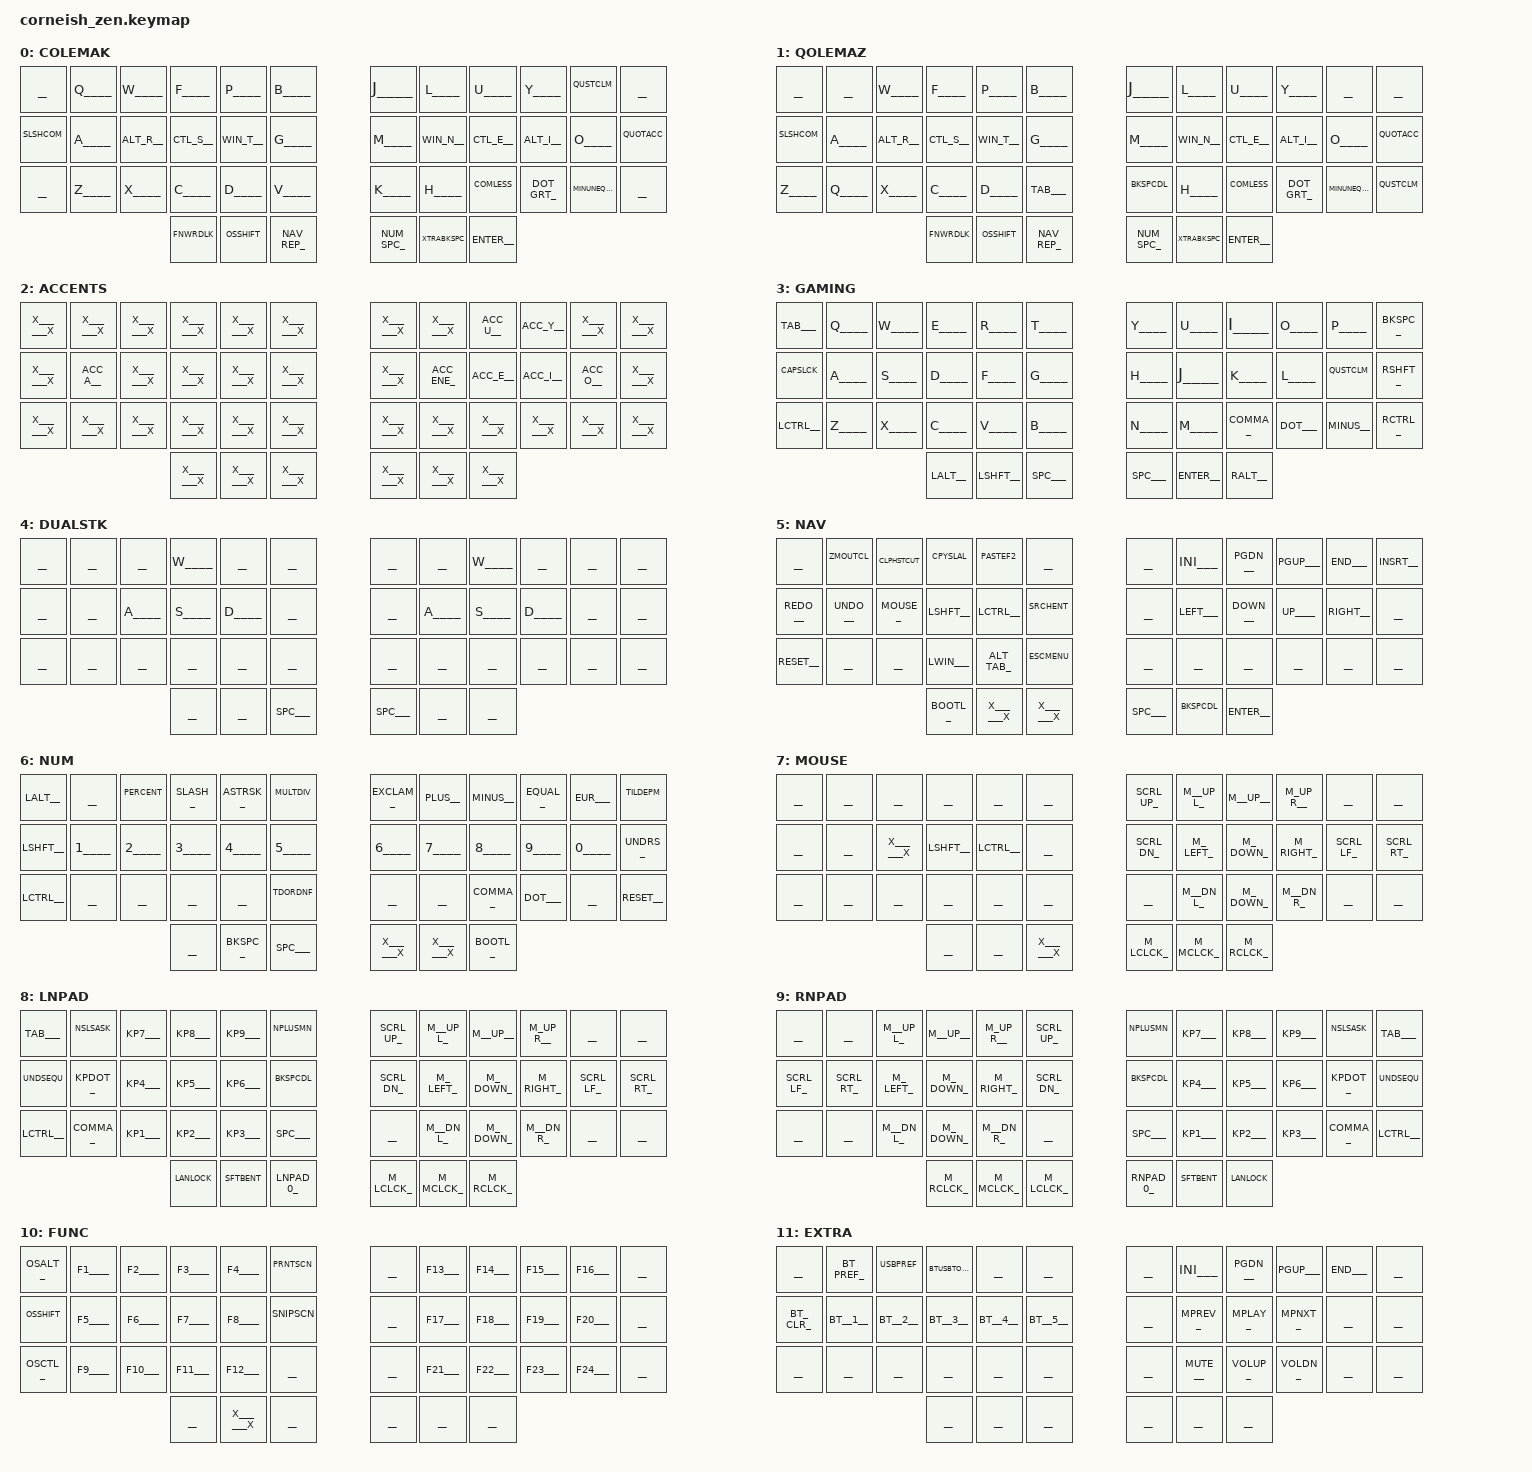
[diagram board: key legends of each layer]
/*
*
* Copyright (c) 2021 Darryl deHaan
* SPDX-License-Identifier: MIT
*
*/

#include <behaviors.dtsi>
#include <dt-bindings/zmk/keys.h>
#include <dt-bindings/zmk/bt.h>
#include <dt-bindings/zmk/outputs.h>

#define TEST 0
#define COLEMAK 1
#define QOLEMAZ 2
#define ACCENTS 3
#define GAMING  4
#define DUALSTK 5
#define NAV 6
#define NUM 7
#define MOUSE 8
#define LNPAD 9
#define RNPAD 10
#define FUNC 11
#define EXTRA 12


#define TEST44s


#include "keycodes.h"
#include <dt-bindings/zmk/mouse.h>

/ {
  chosen {
    zmk,matrix_transform = &default_transform;
    //zmk,matrix_transform = &five_column_transform;
  };
};

&sk {
      release-after-ms = <1500>;
      quick-release;
};  
&mmv {    time-to-max-speed-ms = <1000>;};

/ {

        combos {
              #include "combos.dtsi"
        };
        macros {
              #include "macros.dtsi"
        };
        behaviors {

              #include "behaviors.dtsi"
        };

     
        keymap {
                compatible = "zmk,keymap";




//  Base Layer: TEST
//  ╔═════════╤═════════╤═════════╤═════════╤═════════╤═════════╗                       ╔═════════╤═════════╤═════════╤═════════╤═════════╤═════════╗
//  ║    B    │    Q    │    W    │    F    │    P    │    B    ║                       ║    J    │    L    │    U    │    Y    │    B    │    J    ║
//  ║         │         │         │         │         │         ║                       ║         │         │         │         │         │         ║
//  ╟─────────┼─────────┼─────────┼─────────┼─────────┼─────────╢                       ╟─────────┼─────────┼─────────┼─────────┼─────────┼─────────╢
//  ║    M    │    A    │    R    │    S    │    T    │    G    ║                       ║    M    │    N    │    E    │    I    │    O    │    S    ║
//  ║         │         │         │         │         │         ║                       ║         │         │         │         │         │         ║
//  ╟─────────┼─────────┼─────────┼─────────┼─────────┼─────────║                       ║─────────┼─────────┼─────────┼─────────┼─────────┼─────────╢
//  ║    D    │    Z    │    X    │    C    │    D    │    V    ║                       ║    K    │    H    │    K    │    S    │    J    │   U     ║
//  ║         │         │         │         │         │         ║                       ║         │         │         │         │         │         ║
//  ╚═════════╧═════════╧═════════╧═════════╬─────────┼─────────╬═════════╗   ╔═════════╬─────────┼─────────╬═════════╧═════════╧═════════╧═════════╝
//                                          ║    F    │    P    │    B    ║   ║    J    │    L    │    U    ║
//                                          ║         │         │         ║   ║         │         │         ║
//                                          ╚═════════╧═════════╧═════════╝   ╚═════════╧═════════╧═════════╝
                default_layer { label = "TEST"; bindings = <
     ____B____ ____Q____ ____W____ ____F____ ____P____ ____B____                         ____J____ ____L____ ____U____ ____Y____ ____B____ ____J____
     ____M____ ____A____ ____R____ ____S____ ____T____ ____G____                         ____M____ ____N____ ____E____ ____I____ ____O____ ____S____
     ____D____ ____Z____ ____X____ ____C____ ____D____ ____V____                         ____K____ ____H____ ____K____ ____S____ ____J____ ____U____
                                             ____F____ ____P____ ____B____     ____J____ ____L____ ____U____
                        >;};


//  Base Layer: COLEMAK
//  ╔═════════╤═════════╤═════════╤═════════╤═════════╤═════════╗                       ╔═════════╤═════════╤═════════╤═════════╤═════════╤═════════╗
//  ║         │    Q    │    W    │    F    │    P    │    B    ║                       ║    J    │    L    │    U    │    Y    │   ¡ !   │         ║
//  ║         │         │         │         │         │         ║                       ║         │         │         │         │   ¿ ?   │         ║
//  ╟─────────┼─────────┼─────────┼─────────┼─────────┼─────────╢                       ╟─────────┼─────────┼─────────┼─────────┼─────────┼─────────╢
//  ║  */ /*  │    A    │   ALT   │   CTRL  │   WIN   │    G    ║                       ║    M    │   WIN   │   CTRL  │   ALT   │    O    │   ^ `   ║
//  ║   / \   │         │    R    │    S    │    T    │         ║                       ║         │    N    │    E    │    I    │         │   " '   ║
//  ╟─────────┼─────────┼─────────┼─────────┼─────────┼─────────║                       ║─────────┼─────────┼─────────┼─────────┼─────────┼─────────╢
//  ║         │    Z    │    X    │    C    │    D    │    V    ║                       ║    K    │    H    │   , ;   │   . :   │  → =    │         ║
//  ║         │         │         │         │         │         ║                       ║         │         │         │         │  - _    │         ║
//  ╚═════════╧═════════╧═════════╧═════════╬─────────┼─────────╬═════════╗   ╔═════════╬─────────┼─────────╬═════════╧═════════╧═════════╧═════════╝
//                                          ║ CAPSLCK │  CAPS   │   NAV   ║   ║   NUM   │  EXTRA  │  ENTER  ║
//                                          ║FNC CPWRD│  SHIFT  │   REP   ║   ║   SPC   │  BKSPC  │         ║
//                                          ╚═════════╧═════════╧═════════╝   ╚═════════╧═════════╧═════════╝
                default_layer { label = "COLEMAK"; bindings = <
     _________ ____Q____ ____W____ ____F____ ____P____ ____B____                         ____J____ ____L____ ____U____ ____Y____ _QUSTCLM_ _________
     _SLSHCOM_ ____A____ __ALT_R__ __CTL_S__ __WIN_T__ ____G____                         ____M____ __WIN_N__ __CTL_E__ __ALT_I__ ____O____ _QUOTACC_
     _________ ____Z____ ____X____ ____C____ ____D____ ____V____                         ____K____ ____H____ _COMLESS_ _DOT_GRT_ MINUNEQAR _________
                                             _FNWRDLK_ _OSSHIFT_ _NAV_REP_     _NUM_SPC_ XTRABKSPC __ENTER__
                        >;};

//  Base Layer: QOLEMAZ
//  ╔═════════╤═════════╤═════════╤═════════╤═════════╤═════════╗                       ╔═════════╤═════════╤═════════╤═════════╤═════════╤═════════╗
//  ║         │         │    W    │    F    │    P    │    B    ║                       ║    J    │    L    │    U    │    Y    │         │         ║
//  ║         │         │         │         │         │         ║                       ║         │         │         │         │         │         ║
//  ╟─────────┼─────────┼─────────┼─────────┼─────────┼─────────╢                       ╟─────────┼─────────┼─────────┼─────────┼─────────┼─────────╢
//  ║  */ /*  │    A    │   ALT   │   CTRL  │   WIN   │    G    ║                       ║    M    │   WIN   │   CTRL  │   ALT   │    O    │   ^ `   ║
//  ║   / \   │         │    R    │    S    │    T    │         ║                       ║         │    N    │    E    │    I    │         │   " '   ║
//  ╟─────────┼─────────┼─────────┼─────────┼─────────┼─────────║                       ║─────────┼─────────┼─────────┼─────────┼─────────┼─────────╢
//  ║    Z    │    Q    │    X    │    C    │    D    │   TAB   ║                       ║   DEL   │    H    │   , ;   │   . :   │  → =    │   ¡ !   ║
//  ║         │         │         │         │         │         ║                       ║ BACKSPC │         │         │         │  - _    │   ¿ ?   ║
//  ╚═════════╧═════════╧═════════╧═════════╬─────────┼─────────╬═════════╗   ╔═════════╬─────────┼─────────╬═════════╧═════════╧═════════╧═════════╝
//                                          ║ CAPSLCK │  CAPS   │   NAV   ║   ║   NUM   │  EXTRA  │  ENTER  ║
//                                          ║FNC CPWRD│  SHIFT  │   REP   ║   ║   SPC   │  BKSPC  │         ║
//                                          ╚═════════╧═════════╧═════════╝   ╚═════════╧═════════╧═════════╝
                qolemaz_layer { label = "QOLEMAZ"; bindings = <
     _________ _________ ____W____ ____F____ ____P____ ____B____                         ____J____ ____L____ ____U____ ____Y____ _________ _________
     _SLSHCOM_ ____A____ __ALT_R__ __CTL_S__ __WIN_T__ ____G____                         ____M____ __WIN_N__ __CTL_E__ __ALT_I__ ____O____ _QUOTACC_
     ____Z____ ____Q____ ____X____ ____C____ ____D____ ___TAB___                         _BKSPCDL_ ____H____ _COMLESS_ _DOT_GRT_ MINUNEQAR _QUSTCLM_
                                             _FNWRDLK_ _OSSHIFT_ _NAV_REP_     _NUM_SPC_ XTRABKSPC __ENTER__
                        >;};
             


//  Base Layer: ACCENTS
//  ╔═════════╤═════════╤═════════╤═════════╤═════════╤═════════╗                       ╔═════════╤═════════╤═════════╤═════════╤═════════╤═════════╗
//  ║         │         │         │         │         │         ║                       ║         │         │    Ú    │    Ü    │         │         ║
//  ║         │         │         │         │         │         ║                       ║         │         │    U    │    Y    │         │         ║
//  ╟─────────┼─────────┼─────────┼─────────┼─────────┼─────────╢                       ╟─────────┼─────────┼─────────┼─────────┼─────────┼─────────╢
//  ║         │    Á    │         │         │         │         ║                       ║         │    Ñ    │    É    │    Í    │    Ó    │         ║
//  ║         │    A    │         │         │         │         ║                       ║         │    N    │    E    │    I    │    O    │         ║
//  ╟─────────┼─────────┼─────────┼─────────┼─────────┼─────────║                       ║─────────┼─────────┼─────────┼─────────┼─────────┼─────────╢
//  ║         │         │         │         │         │         ║                       ║         │         │         │         │         │         ║
//  ║         │         │         │         │         │         ║                       ║         │         │         │         │         │         ║
//  ╚═════════╧═════════╧═════════╧═════════╬─────────┼─────────╬═════════╗   ╔═════════╬─────────┼─────────╬═════════╧═════════╧═════════╧═════════╝
//                                          ║         │         │         ║   ║         │         │         ║
//                                          ║         │         │         ║   ║         │         │         ║
//                                          ╚═════════╧═════════╧═════════╝   ╚═════════╧═════════╧═════════╝
                letter_accents_layer { label = "ACCENTS"; bindings = <
     X_______X X_______X X_______X X_______X X_______X X_______X                         X_______X X_______X __ACC_U__ __ACC_Y__ X_______X X_______X
     X_______X __ACC_A__ X_______X X_______X X_______X X_______X                         X_______X _ACC_ENE_ __ACC_E__ __ACC_I__ __ACC_O__ X_______X
     X_______X X_______X X_______X X_______X X_______X X_______X                         X_______X X_______X X_______X X_______X X_______X X_______X
                                             X_______X X_______X X_______X     X_______X X_______X X_______X
                        >;};

//  Base Layer: GAMING
//  ╔═════════╤═════════╤═════════╤═════════╤═════════╤═════════╗                       ╔═════════╤═════════╤═════════╤═════════╤═════════╤═════════╗
//  ║  TAB    │    Q    │    W    │    E    │    R    │    T    ║                       ║    Y    │    U    │    I    │    O    │    P    │ BCKSPC  ║
//  ║         │         │         │         │         │         ║                       ║         │         │         │         │         │         ║
//  ╟─────────┼─────────┼─────────┼─────────┼─────────┼─────────╢                       ╟─────────┼─────────┼─────────┼─────────┼─────────┼─────────╢
//  ║ CAPSLCK │    A    │    S    │    D    │    F    │    G    ║                       ║    H    │    J    │    K    │    L    │   ! ¡   │  RSHFT  ║
//  ║         │         │         │         │         │         ║                       ║         │         │         │         │   ? ¿   │         ║
//  ╟─────────┼─────────┼─────────┼─────────┼─────────┼─────────║                       ║─────────┼─────────┼─────────┼─────────┼─────────┼─────────╢
//  ║  LCTRL  │    Z    │    X    │    C    │    V    │    B    ║                       ║    N    │    M    │   , ;   │   . :   │  - _    │  RCTRL  ║
//  ║         │         │         │         │         │         ║                       ║         │         │         │         │         │         ║
//  ╚═════════╧═════════╧═════════╧═════════╬─────────┼─────────╬═════════╗   ╔═════════╬─────────┼─────────╬═════════╧═════════╧═════════╧═════════╝
//                                          ║  LALT   │  SHIFT  │   SPC   ║   ║   SPC   │  ENTER  │  RALT   ║
//                                          ║         │         │         ║   ║         │         │         ║
//                                          ╚═════════╧═════════╧═════════╝   ╚═════════╧═════════╧═════════╝
                gaming_layer { label = "GAMING"; bindings = <
     ___TAB___ ____Q____ ____W____ ____E____ ____R____ ____T____                         ____Y____ ____U____ ____I____ ____O____ ____P____ __BKSPC__
     _CAPSLCK_ ____A____ ____S____ ____D____ ____F____ ____G____                         ____H____ ____J____ ____K____ ____L____ _QUSTCLM_ __RSHFT__
     __LCTRL__ ____Z____ ____X____ ____C____ ____V____ ____B____                         ____N____ ____M____ __COMMA__ ___DOT___ __MINUS__ __RCTRL__
                                             ___LALT__ __LSHFT__ ___SPC___     ___SPC___ __ENTER__ ___RALT__
                        >;};


//  Base Layer: DUALSTK
//  ╔═════════╤═════════╤═════════╤═════════╤═════════╤═════════╗                       ╔═════════╤═════════╤═════════╤═════════╤═════════╤═════════╗
//  ║         │         │         │    W    │         │         ║                       ║         │         │    W    │         │         │         ║
//  ║         │         │         │         │         │         ║                       ║         │         │         │         │         │         ║
//  ╟─────────┼─────────┼─────────┼─────────┼─────────┼─────────╢                       ╟─────────┼─────────┼─────────┼─────────┼─────────┼─────────╢
//  ║         │         │    A    │    S    │    D    │         ║                       ║         │    A    │    S    │    D    │         │         ║
//  ║         │         │         │         │         │         ║                       ║         │         │         │         │         │         ║
//  ╟─────────┼─────────┼─────────┼─────────┼─────────┼─────────║                       ║─────────┼─────────┼─────────┼─────────┼─────────┼─────────╢
//  ║         │         │         │         │         │         ║                       ║         │         │         │         │         │         ║
//  ║         │         │         │         │         │         ║                       ║         │         │         │         │         │         ║
//  ╚═════════╧═════════╧═════════╧═════════╬─────────┼─────────╬═════════╗   ╔═════════╬─────────┼─────────╬═════════╧═════════╧═════════╧═════════╝
//                                          ║         │         │   SPC   ║   ║   SPC   │         │         ║
//                                          ║         │         │         ║   ║         │         │         ║
//                                          ╚═════════╧═════════╧═════════╝   ╚═════════╧═════════╧═════════╝
                dual_stick_layer { label = "DUALSTK"; bindings = <
     _________ _________ _________ ____W____ _________ _________                         _________ _________ ____W____ _________ _________ _________
     _________ _________ ____A____ ____S____ ____D____ _________                         _________ ____A____ ____S____ ____D____ _________ _________
     _________ _________ _________ _________ _________ _________                         _________ _________ _________ _________ _________ _________
                                             _________ _________ ___SPC___     ___SPC___ _________ _________
                        >;};



//  Base Layer: NAV
//  ╔═════════╤═════════╤═════════╤═════════╤═════════╤═════════╗                       ╔═════════╤═════════╤═════════╤═════════╤═════════╤═════════╗
//  ║         │ZOOM  CLS│CLIP HIST│SELECTALL│   F2    │         ║                       ║         │   INI   │  PREPAG │  AVPAG  │   END   │  INSERT ║
//  ║         │ZOOM +/- │   CUT   │  COPY   │  PASTE  │         ║                       ║         │         │         │         │         │         ║
//  ╟─────────┼─────────┼─────────┼─────────┼─────────┼─────────╢                       ╟─────────┼─────────┼─────────┼─────────┼─────────┼─────────╢
//  ║  REDO   │  UNDO   │  MOUSE  │  SHIFT  │  CTRL   │ SEARCH  ║                       ║         │  LEFT   │  DOWN   │   UP    │  RIGHT  │         ║
//  ║         │         │         │         │         │  ENTER  ║                       ║         │         │         │         │         │         ║
//  ╟─────────┼─────────┼─────────┼─────────┼─────────┼─────────║                       ║─────────┼─────────┼─────────┼─────────┼─────────┼─────────╢
//  ║  RESET  │         │         │  LWIN   │ ALT+TAB │   MENU  ║                       ║         │         │         │         │         │         ║
//  ║  SOFT   │         │         │         │         │   ESC   ║                       ║         │         │         │         │         │         ║
//  ╚═════════╧═════════╧═════════╧═════════╬─────────┼─────────╬═════════╗   ╔═════════╬─────────┼─────────╬═════════╧═════════╧═════════╧═════════╝
//                                          ║  RESET  │         │XXXXXXXXX║   ║   SPC   │   DEL   │  ENTER  ║
//                                          ║  BOOTL  │         │XXXXXXXXX║   ║         │  BKSPC  │         ║
//                                          ╚═════════╧═════════╧═════════╝   ╚═════════╧═════════╧═════════╝
                navigation_layer { label = "NAV"; bindings = <
     _________ _ZMOUTCL_ CLPHSTCUT _CPYSLAL_ _PASTEF2_ _________                         _________ ___INI___ __PGDN___ __PGUP___ ___END___ __INSRT__
     __REDO___ __UNDO___ __MOUSE__ __LSHFT__ __LCTRL__ _SRCHENT_                         _________ __LEFT___ __DOWN___ ___UP____ __RIGHT__ _________
     __RESET__ _________ _________ __LWIN___ _ALT_TAB_ _ESCMENU_                         _________ _________ _________ _________ _________ _________
                                             __BOOTL__ X_______X X_______X     ___SPC___ _BKSPCDL_ __ENTER__
                        >;};



//  Base Layer: NUM
//  ╔═════════╤═════════╤═════════╤═════════╤═════════╤═════════╗                       ╔═════════╤═════════╤═════════╤═════════╤═════════╤═════════╗
//  ║   ALT   │         │    %    │    /    │    *    │    ÷    ║                       ║    !    │    +    │    -    │    =    │    €    │    ±    ║
//  ║         │         │         │         │         │    ×    ║                       ║         │         │         │         │         │    ~    ║
//  ╟─────────┼─────────┼─────────┼─────────┼─────────┼─────────╢                       ╟─────────┼─────────┼─────────┼─────────┼─────────┼─────────╢
//  ║  SHIFT  │    1    │    2    │    3    │    4    │    5    ║                       ║    6    │    7    │    8    │    9    │    0    │    _    ║
//  ║         │         │         │         │         │         ║                       ║         │         │         │         │         │         ║
//  ╟─────────┼─────────┼─────────┼─────────┼─────────┼─────────║                       ║─────────┼─────────┼─────────┼─────────┼─────────┼─────────╢
//  ║  LCTRL  │         │         │         │         │  ¼ ½ ∞  ║                       ║         │         │    ,    │    .    │         │  RESET  ║
//  ║         │         │         │         │         │  ³ ² º  ║                       ║         │         │         │         │         │  SOFT   ║
//  ╚═════════╧═════════╧═════════╧═════════╬─────────┼─────────╬═════════╗   ╔═════════╬─────────┼─────────╬═════════╧═════════╧═════════╧═════════╝
//                                          ║         │ BCKSPC  │   SPC   ║   ║XXXXXXXXX│         │  RESET  ║
//                                          ║         │         │         ║   ║XXXXXXXXX│         │  BOOTL  ║
//                                          ╚═════════╧═════════╧═════════╝   ╚═════════╧═════════╧═════════╝
//  
                num_layer { label = "NUM"; bindings = <
     ___LALT__ _________ _PERCENT_ __SLASH__ _ASTRSK__ _MULTDIV_                         _EXCLAM__ ___PLUS__ __MINUS__ __EQUAL__ ___EUR___ _TILDEPM_
     __LSHFT__ ____1____ ____2____ ____3____ ____4____ ____5____                         ____6____ ____7____ ____8____ ____9____ ____0____ __UNDRS__
     __LCTRL__ _________ _________ _________ _________ _TDORDNF_                         _________ _________ __COMMA__ ___DOT___ _________ __RESET__
                                             _________ __BKSPC__ ___SPC___     X_______X X_______X __BOOTL__
                        >;};


//  Base Layer: MOUSE
//  ╔═════════╤═════════╤═════════╤═════════╤═════════╤═════════╗                       ╔═════════╤═════════╤═════════╤═════════╤═════════╤═════════╗
//  ║         │         │         │         │         │         ║                       ║ SCROLL  │   U-L   │    U    │   U-R   │         │         ║
//  ║         │         │         │         │         │         ║                       ║   UP    │         │         │         │         │         ║
//  ╟─────────┼─────────┼─────────┼─────────┼─────────┼─────────╢                       ╟─────────┼─────────┼─────────┼─────────┼─────────┼─────────╢
//  ║         │         │XXXXXXXXX│  SHIFT  │  CTRL   │         ║                       ║ SCROLL  │    L    │    D    │    R    │ SCROLL  │ SCROLL  ║
//  ║         │         │XXXXXXXXX│         │         │         ║                       ║   DN    │         │         │         │  LEFT   │  RIGHT  ║
//  ╟─────────┼─────────┼─────────┼─────────┼─────────┼─────────║                       ║─────────┼─────────┼─────────┼─────────┼─────────┼─────────╢
//  ║         │         │         │         │         │         ║                       ║         │   D-L   │    D    │   D-R   │         │         ║
//  ║         │         │         │         │         │         ║                       ║         │         │         │         │         │         ║
//  ╚═════════╧═════════╧═════════╧═════════╬─────────┼─────────╬═════════╗   ╔═════════╬─────────┼─────────╬═════════╧═════════╧═════════╧═════════╝
//                                          ║         │         │XXXXXXXXX║   ║  LEFT   │   MID   │  RIGHT  ║
//                                          ║         │         │XXXXXXXXX║   ║  CLICK  │  CLICK  │  CLICK  ║
//                                          ╚═════════╧═════════╧═════════╝   ╚═════════╧═════════╧═════════╝
//  
                mouse_layer { label = "MOUSE"; bindings = <
     _________ _________ _________ _________ _________ _________                         _SCRL_UP_ _M__UP_L_ __M__UP__ _M_UP_R__ _________ _________
     _________ _________ X_______X __LSHFT__ __LCTRL__ _________                         _SCRL_DN_ _M__LEFT_ _M__DOWN_ _M_RIGHT_ _SCRL_LF_ _SCRL_RT_
     _________ _________ _________ _________ _________ _________                         _________ _M__DN_L_ _M__DOWN_ _M__DN_R_ _________ _________
                                             _________ _________ X_______X     _M_LCLCK_ _M_MCLCK_ _M_RCLCK_
                        >;};




//  Base Layer: LNPAD
//  ╔═════════╤═════════╤═════════╤═════════╤═════════╤═════════╗                       ╔═════════╤═════════╤═════════╤═════════╤═════════╤═════════╗
//  ║   TAB   │    *    │    7    │    8    │    9    │    -    ║                       ║ SCROLL  │   U-L   │    U    │   U-R   │         │         ║
//  ║         │    /    │         │         │         │    +    ║                       ║   UP    │         │         │         │         │         ║
//  ╟─────────┼─────────┼─────────┼─────────┼─────────┼─────────╢                       ╟─────────┼─────────┼─────────┼─────────┼─────────┼─────────╢
//  ║  EQUAL  │    .    │    4    │    5    │    6    │ DELETE  ║                       ║ SCROLL  │    L    │    D    │    R    │ SCROLL  │ SCROLL  ║
//  ║ UNDERSC │         │         │         │         │ BCKSPC  ║                       ║   DN    │         │         │         │  LEFT   │  RIGHT  ║
//  ╟─────────┼─────────┼─────────┼─────────┼─────────┼─────────║                       ║─────────┼─────────┼─────────┼─────────┼─────────┼─────────╢
//  ║  LCTRL  │    ,    │    1    │    2    │    3    │   SPC   ║                       ║         │   D-L   │    D    │   D-R   │         │         ║
//  ║         │         │         │         │         │         ║                       ║         │         │         │         │         │         ║
//  ╚═════════╧═════════╧═════════╧═════════╬─────────┼─────────╬═════════╗   ╔═════════╬─────────┼─────────╬═════════╧═════════╧═════════╧═════════╝
//                                          ║  LALT   │ LSHIFT  │XXXXXXXXX║   ║  LEFT   │   MID   │  RIGHT  ║
//                                          ║  NLOCK  │  ENTER  │XXXXXXXXX║   ║  CLICK  │  CLICK  │  CLICK  ║
//                                          ╚═════════╧═════════╧═════════╝   ╚═════════╧═════════╧═════════╝
//  
                left_numpad_layer { label = "LNPAD"; bindings = <
     ___TAB___ _NSLSASK_ ___KP7___ ___KP8___ ___KP9___ _NPLUSMN_                         _SCRL_UP_ _M__UP_L_ __M__UP__ _M_UP_R__ _________ _________
     _UNDSEQU_ __KPDOT__ ___KP4___ ___KP5___ ___KP6___ _BKSPCDL_                         _SCRL_DN_ _M__LEFT_ _M__DOWN_ _M_RIGHT_ _SCRL_LF_ _SCRL_RT_
     __LCTRL__ __COMMA__ ___KP1___ ___KP2___ ___KP3___ ___SPC___                         _________ _M__DN_L_ _M__DOWN_ _M__DN_R_ _________ _________
                                             _LANLOCK_ _SFTBENT_ _LNPAD_0_     _M_LCLCK_ _M_MCLCK_ _M_RCLCK_
                        >;};



//  Base Layer: RNPAD
//  ╔═════════╤═════════╤═════════╤═════════╤═════════╤═════════╗                       ╔═════════╤═════════╤═════════╤═════════╤═════════╤═════════╗
//  ║         │         │   U-L   │    U    │   U-R   │ SCROLL  ║                       ║    -    │    7    │    8    │    9    │    *    │   TAB   ║
//  ║         │         │         │         │         │   UP    ║                       ║    +    │         │         │         │    /    │         ║
//  ╟─────────┼─────────┼─────────┼─────────┼─────────┼─────────╢                       ╟─────────┼─────────┼─────────┼─────────┼─────────┼─────────╢
//  ║ SCROLL  │ SCROLL  │    L    │    D    │    R    │ SCROLL  ║                       ║ DELETE  │    4    │    5    │    6    │    .    │  EQUAL  ║
//  ║         │         │         │         │         │   DN    ║                       ║ BCKSPC  │         │         │         │         │ UNDERSC ║
//  ╟─────────┼─────────┼─────────┼─────────┼─────────┼─────────║                       ║─────────┼─────────┼─────────┼─────────┼─────────┼─────────╢
//  ║         │         │   D-L   │   D-L   │   D-R   │   D-L   ║                       ║   SPC   │    1    │    2    │    3    │    ,    │  RCTRL  ║
//  ║         │         │         │         │         │         ║                       ║         │         │         │         │         │         ║
//  ╚═════════╧═════════╧═════════╧═════════╬─────────┼─────────╬═════════╗   ╔═════════╬─────────┼─────────╬═════════╧═════════╧═════════╧═════════╝
//                                          ║  RIGHT  │   MID   │  LEFT   ║   ║XXXXXXXXX│ LSHIFT  │  LALT   ║
//                                          ║  CLICK  │  CLICK  │  CLICK  ║   ║XXXXXXXXX│  ENTER  │  NLOCK  ║
//                                          ╚═════════╧═════════╧═════════╝   ╚═════════╧═════════╧═════════╝
//  
                right_numpad_layer { label = "RNPAD"; bindings = <
     _________ _________ _M__UP_L_ __M__UP__ _M_UP_R__ _SCRL_UP_                         _NPLUSMN_ ___KP7___ ___KP8___ ___KP9___ _NSLSASK_ ___TAB___
     _SCRL_LF_ _SCRL_RT_ _M__LEFT_ _M__DOWN_ _M_RIGHT_ _SCRL_DN_                         _BKSPCDL_ ___KP4___ ___KP5___ ___KP6___ __KPDOT__ _UNDSEQU_
     _________ _________ _M__DN_L_ _M__DOWN_ _M__DN_R_ _________                         ___SPC___ ___KP1___ ___KP2___ ___KP3___ __COMMA__ __LCTRL__
                                             _M_RCLCK_ _M_MCLCK_ _M_LCLCK_     _RNPAD_0_ _SFTBENT_ _LANLOCK_
                        >;};




//  Base Layer: FUNC
//  ╔═════════╤═════════╤═════════╤═════════╤═════════╤═════════╗                       ╔═════════╤═════════╤═════════╤═════════╤═════════╤═════════╗
//  ║ ONESHOT │   F1    │   F2    │   F3    │   F4    │  PRINT  ║                       ║         │   F13   │   F14   │   F15   │   F16   │         ║
//  ║   ALT   │         │         │         │         │ SCREEN  ║                       ║         │         │         │         │         │         ║
//  ╟─────────┼─────────┼─────────┼─────────┼─────────┼─────────╢                       ╟─────────┼─────────┼─────────┼─────────┼─────────┼─────────╢
//  ║ ONESHOT │   F5    │   F6    │   F7    │   F8    │  SNIP   ║                       ║         │   F17   │   F18   │   F19   │   F20   │         ║
//  ║  SHIFT  │         │         │         │         │ SCREEN  ║                       ║         │         │         │         │         │         ║
//  ╟─────────┼─────────┼─────────┼─────────┼─────────┼─────────║                       ║─────────┼─────────┼─────────┼─────────┼─────────┼─────────╢
//  ║ ONESHOT │   F9    │   F10   │   F11   │   F12   │         ║                       ║         │   F21   │   F22   │   F23   │   F24   │         ║
//  ║  CTRL   │         │         │         │         │         ║                       ║         │         │         │         │         │         ║
//  ╚═════════╧═════════╧═════════╧═════════╬─────────┼─────────╬═════════╗   ╔═════════╬─────────┼─────────╬═════════╧═════════╧═════════╧═════════╝
//                                          ║         │XXXXXXXXX│         ║   ║         │         │         ║
//                                          ║         │XXXXXXXXX│         ║   ║         │         │         ║
//                                          ╚═════════╧═════════╧═════════╝   ╚═════════╧═════════╧═════════╝
//  

                function_layer { label = "FUNC"; bindings = <
     __OSALT__ ___F1____ ___F2____ ___F3____ ___F4____ _PRNTSCN_                         _________ ___F13___ ___F14___ ___F15___ ___F16___ _________
     _OSSHIFT_ ___F5____ ___F6____ ___F7____ ___F8____ _SNIPSCN_                         _________ ___F17___ ___F18___ ___F19___ ___F20___ _________
     __OSCTL__ ___F9____ ___F10___ ___F11___ ___F12___ _________                         _________ ___F21___ ___F22___ ___F23___ ___F24___ _________
                                             _________ X_______X _________     _________ _________ _________
                        >;};


//  Base Layer: EXTRA
//  ╔═════════╤═════════╤═════════╤═════════╤═════════╤═════════╗                       ╔═════════╤═════════╤═════════╤═════════╤═════════╤═════════╗
//  ║         │   BT    │   USB   │ BT  USB │         │         ║                       ║         │   INI   │  AVPAG  │ PREPAG  │   END   │         ║
//  ║         │PREFERRED│PREFERRED│ TOGGLE  │         │         ║                       ║         │         │         │         │         │         ║
//  ╟─────────┼─────────┼─────────┼─────────┼─────────┼─────────╢                       ╟─────────┼─────────┼─────────┼─────────┼─────────┼─────────╢
//  ║   BT    │   BT    │   BT    │   BT    │   BT    │   BT    ║                       ║         │  MEDIA  │  MEDIA  │  MEDIA  │         │         ║
//  ║  CLEAR  │    1    │    2    │    3    │    4    │    5    ║                       ║         │  PREV   │  PLAY   │  NEXT   │         │         ║
//  ╟─────────┼─────────┼─────────┼─────────┼─────────┼─────────║                       ║─────────┼─────────┼─────────┼─────────┼─────────┼─────────╢
//  ║         │         │         │         │         │         ║                       ║         │   VOL   │   VOL   │   VOL   │         │         ║
//  ║         │         │         │         │         │         ║                       ║         │  MUTE   │    UP   │   DWN   │         │         ║
//  ╚═════════╧═════════╧═════════╧═════════╬─────────┼─────────╬═════════╗   ╔═════════╬─────────┼─────────╬═════════╧═════════╧═════════╧═════════╝
//                                          ║         │         │         ║   ║         │         │         ║
//                                          ║         │         │         ║   ║         │         │         ║
//                                          ╚═════════╧═════════╧═════════╝   ╚═════════╧═════════╧═════════╝
//  

                extra_layer { label = "EXTRA"; bindings = <
     _________ _BT_PREF_ _USBPREF_ BTUSBTOGG _________ _________                         _________ ___INI___ __PGDN___ __PGUP___ ___END___ _________
     _BT__CLR_ __BT__1__ __BT__2__ __BT__3__ __BT__4__ __BT__5__                         _________ __MPREV__ __MPLAY__ __MPNXT__ _________ _________
     _________ _________ _________ _________ _________ _________                         _________ __MUTE___ __VOLUP__ __VOLDN__ _________ _________
                                             _________ _________ _________     _________ _________ _________
                        >;};




//  Base Layer: BLANK
//  ╔═════════╤═════════╤═════════╤═════════╤═════════╤═════════╗                       ╔═════════╤═════════╤═════════╤═════════╤═════════╤═════════╗
//  ║         │         │         │         │         │         ║                       ║         │         │         │         │         │         ║
//  ║         │         │         │         │         │         ║                       ║         │         │         │         │         │         ║
//  ╟─────────┼─────────┼─────────┼─────────┼─────────┼─────────╢                       ╟─────────┼─────────┼─────────┼─────────┼─────────┼─────────╢
//  ║         │         │         │         │         │         ║                       ║         │         │         │         │         │         ║
//  ║         │         │         │         │         │         ║                       ║         │         │         │         │         │         ║
//  ╟─────────┼─────────┼─────────┼─────────┼─────────┼─────────║                       ║─────────┼─────────┼─────────┼─────────┼─────────┼─────────╢
//  ║         │         │         │         │         │         ║                       ║         │         │         │         │         │         ║
//  ║         │         │         │         │         │         ║                       ║         │         │         │         │         │         ║
//  ╚═════════╧═════════╧═════════╧═════════╬─────────┼─────────╬═════════╗   ╔═════════╬─────────┼─────────╬═════════╧═════════╧═════════╧═════════╝
//                                          ║         │         │         ║   ║         │         │         ║
//                                          ║         │         │         ║   ║         │         │         ║
//                                          ╚═════════╧═════════╧═════════╝   ╚═════════╧═════════╧═════════╝
//  
/*
                numpad_layer { label = "NPAD"; bindings = <
     _________ _________ _________ _________ _________ _________                         _________ _________ _________ _________ _________ _________
     _________ _________ _________ _________ _________ _________                         _________ _________ _________ _________ _________ _________
     _________ _________ _________ _________ _________ _________                         _________ _________ _________ _________ _________ _________
                                             _________ _________ _________     _________ _________ _________
                        >;};

*/


        };
};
